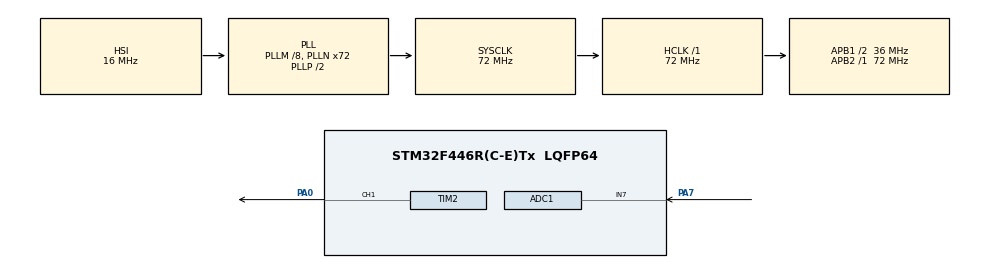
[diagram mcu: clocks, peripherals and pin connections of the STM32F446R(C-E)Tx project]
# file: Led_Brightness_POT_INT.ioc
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ADC1.Channel-0\#ChannelRegularConversion=ADC_CHANNEL_7
ADC1.NbrOfConversionFlag=1
ADC1.Rank-0\#ChannelRegularConversion=1
ADC1.SamplingTime-0\#ChannelRegularConversion=ADC_SAMPLETIME_3CYCLES
ADC1.master=1
Mcu.Family=STM32F4
Mcu.Name=STM32F446R(C-E)Tx
Mcu.Package=LQFP64
NVIC.ADC_IRQn=true\:0\:0\:false\:false\:true\:true\:true\:true
NVIC.PriorityGroup=NVIC_PRIORITYGROUP_0
PA0-WKUP.Signal=S_TIM2_CH1_ETR
PA7.Signal=ADCx_IN7
PH0-OSC_IN.Mode=HSE-External-Oscillator
PH0-OSC_IN.Signal=RCC_OSC_IN
PH1-OSC_OUT.Mode=HSE-External-Oscillator
PH1-OSC_OUT.Signal=RCC_OSC_OUT
ProjectManager.HeapSize=0x200
ProjectManager.StackSize=0x400
ProjectManager.TargetToolchain=STM32CubeIDE
RCC.48MHZClocksFreq_Value=84000000
RCC.AHBFreq_Value=72000000
RCC.APB1CLKDivider=RCC_HCLK_DIV2
RCC.APB1Freq_Value=36000000
RCC.APB1TimFreq_Value=72000000
RCC.APB2Freq_Value=72000000
RCC.APB2TimFreq_Value=72000000
RCC.CortexFreq_Value=72000000
RCC.FLatency-AdvancedSettings=FLASH_LATENCY_2
RCC.HCLKFreq_Value=72000000
RCC.HSE_VALUE=8000000
RCC.HSI_VALUE=16000000
RCC.PLLM=8
RCC.PLLN=72
RCC.SYSCLKFreq_VALUE=72000000
RCC.SYSCLKSource=RCC_SYSCLKSOURCE_PLLCLK
RCC.USBFreq_Value=72000000
RCC.VCOOutputFreq_Value=144000000
SH.ADCx_IN7.0=ADC1_IN7,IN7
SH.S_TIM2_CH1_ETR.0=TIM2_CH1,PWM Generation1 CH1
TIM2.AutoReloadPreload=TIM_AUTORELOAD_PRELOAD_ENABLE
TIM2.Channel-PWM\ Generation1\ CH1=TIM_CHANNEL_1
TIM2.Period=65536
VP_TIM2_VS_ClockSourceINT.Mode=Internal
board=NUCLEO-F446RE

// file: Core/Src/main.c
/* USER CODE BEGIN Header */
/**
  ******************************************************************************
  * @file           : main.c
  * @brief          : Main program body
  ******************************************************************************
  * @attention
  *
  * Copyright (c) 2024 STMicroelectronics.
  * All rights reserved.
  *
  * This software is licensed under terms that can be found in the LICENSE file
  * in the root directory of this software component.
  * If no LICENSE file comes with this software, it is provided AS-IS.
  *
  ******************************************************************************
  */
/* USER CODE END Header */
#include "main.h"

ADC_HandleTypeDef hadc1;

TIM_HandleTypeDef htim2;

/* USER CODE BEGIN PV */
uint16_t adc_data = 0;
uint16_t pwm_value = 0;
/* USER CODE END PV */

void SystemClock_Config(void);
static void MX_GPIO_Init(void);
static void MX_ADC1_Init(void);
static void MX_TIM2_Init(void);

int main(void)
{

  /* MCU Configuration--------------------------------------------------------*/

  /* Reset of all peripherals, Initializes the Flash interface and the Systick. */
  HAL_Init();

  /* Configure the system clock */
  SystemClock_Config();

  /* Initialize all configured peripherals */
  MX_GPIO_Init();
  MX_ADC1_Init();
  MX_TIM2_Init();
  /* USER CODE BEGIN 2 */
  HAL_TIM_PWM_Start(&htim2, TIM_CHANNEL_1);
  /* USER CODE END 2 */

  /* Infinite loop */
  /* USER CODE BEGIN WHILE */
  while (1)
  {
	  HAL_ADC_Start_IT(&hadc1);
	  pwm_value = (adc_data << 3);
	  TIM2->CCR1 = pwm_value;

	  HAL_Delay(1);
    /* USER CODE END WHILE */

  }
}

void SystemClock_Config(void)
{
  RCC_OscInitTypeDef RCC_OscInitStruct = {0};
  RCC_ClkInitTypeDef RCC_ClkInitStruct = {0};

  /** Configure the main internal regulator output voltage
  */
  __HAL_RCC_PWR_CLK_ENABLE();
  __HAL_PWR_VOLTAGESCALING_CONFIG(PWR_REGULATOR_VOLTAGE_SCALE3);

  /** Initializes the RCC Oscillators according to the specified parameters
  * in the RCC_OscInitTypeDef structure.
  */
  RCC_OscInitStruct.OscillatorType = RCC_OSCILLATORTYPE_HSI;
  RCC_OscInitStruct.HSIState = RCC_HSI_ON;
  RCC_OscInitStruct.HSICalibrationValue = RCC_HSICALIBRATION_DEFAULT;
  RCC_OscInitStruct.PLL.PLLState = RCC_PLL_ON;
  RCC_OscInitStruct.PLL.PLLSource = RCC_PLLSOURCE_HSI;
  RCC_OscInitStruct.PLL.PLLM = 8;
  RCC_OscInitStruct.PLL.PLLN = 72;
  RCC_OscInitStruct.PLL.PLLP = RCC_PLLP_DIV2;
  RCC_OscInitStruct.PLL.PLLQ = 2;
  RCC_OscInitStruct.PLL.PLLR = 2;
  if (HAL_RCC_OscConfig(&RCC_OscInitStruct) != HAL_OK)
  {
    Error_Handler();
  }

  /** Initializes the CPU, AHB and APB buses clocks
  */
  RCC_ClkInitStruct.ClockType = RCC_CLOCKTYPE_HCLK|RCC_CLOCKTYPE_SYSCLK
                              |RCC_CLOCKTYPE_PCLK1|RCC_CLOCKTYPE_PCLK2;
  RCC_ClkInitStruct.SYSCLKSource = RCC_SYSCLKSOURCE_PLLCLK;
  RCC_ClkInitStruct.AHBCLKDivider = RCC_SYSCLK_DIV1;
  RCC_ClkInitStruct.APB1CLKDivider = RCC_HCLK_DIV2;
  RCC_ClkInitStruct.APB2CLKDivider = RCC_HCLK_DIV1;

  if (HAL_RCC_ClockConfig(&RCC_ClkInitStruct, FLASH_LATENCY_2) != HAL_OK)
  {
    Error_Handler();
  }
}

static void MX_ADC1_Init(void)
{

  ADC_ChannelConfTypeDef sConfig = {0};

  /** Configure the global features of the ADC (Clock, Resolution, Data Alignment and number of conversion)
  */
  hadc1.Instance = ADC1;
  hadc1.Init.ClockPrescaler = ADC_CLOCK_SYNC_PCLK_DIV2;
  hadc1.Init.Resolution = ADC_RESOLUTION_12B;
  hadc1.Init.ScanConvMode = DISABLE;
  hadc1.Init.ContinuousConvMode = DISABLE;
  hadc1.Init.DiscontinuousConvMode = DISABLE;
  hadc1.Init.ExternalTrigConvEdge = ADC_EXTERNALTRIGCONVEDGE_NONE;
  hadc1.Init.ExternalTrigConv = ADC_SOFTWARE_START;
  hadc1.Init.DataAlign = ADC_DATAALIGN_RIGHT;
  hadc1.Init.NbrOfConversion = 1;
  hadc1.Init.DMAContinuousRequests = DISABLE;
  hadc1.Init.EOCSelection = ADC_EOC_SINGLE_CONV;
  if (HAL_ADC_Init(&hadc1) != HAL_OK)
  {
    Error_Handler();
  }

  /** Configure for the selected ADC regular channel its corresponding rank in the sequencer and its sample time.
  */
  sConfig.Channel = ADC_CHANNEL_7;
  sConfig.Rank = 1;
  sConfig.SamplingTime = ADC_SAMPLETIME_3CYCLES;
  if (HAL_ADC_ConfigChannel(&hadc1, &sConfig) != HAL_OK)
  {
    Error_Handler();
  }

}

static void MX_TIM2_Init(void)
{

  TIM_ClockConfigTypeDef sClockSourceConfig = {0};
  TIM_MasterConfigTypeDef sMasterConfig = {0};
  TIM_OC_InitTypeDef sConfigOC = {0};

  htim2.Instance = TIM2;
  htim2.Init.Prescaler = 0;
  htim2.Init.CounterMode = TIM_COUNTERMODE_UP;
  htim2.Init.Period = 65536;
  htim2.Init.ClockDivision = TIM_CLOCKDIVISION_DIV1;
  htim2.Init.AutoReloadPreload = TIM_AUTORELOAD_PRELOAD_ENABLE;
  if (HAL_TIM_Base_Init(&htim2) != HAL_OK)
  {
    Error_Handler();
  }
  sClockSourceConfig.ClockSource = TIM_CLOCKSOURCE_INTERNAL;
  if (HAL_TIM_ConfigClockSource(&htim2, &sClockSourceConfig) != HAL_OK)
  {
    Error_Handler();
  }
  if (HAL_TIM_PWM_Init(&htim2) != HAL_OK)
  {
    Error_Handler();
  }
  sMasterConfig.MasterOutputTrigger = TIM_TRGO_RESET;
  sMasterConfig.MasterSlaveMode = TIM_MASTERSLAVEMODE_DISABLE;
  if (HAL_TIMEx_MasterConfigSynchronization(&htim2, &sMasterConfig) != HAL_OK)
  {
    Error_Handler();
  }
  sConfigOC.OCMode = TIM_OCMODE_PWM1;
  sConfigOC.Pulse = 0;
  sConfigOC.OCPolarity = TIM_OCPOLARITY_HIGH;
  sConfigOC.OCFastMode = TIM_OCFAST_DISABLE;
  if (HAL_TIM_PWM_ConfigChannel(&htim2, &sConfigOC, TIM_CHANNEL_1) != HAL_OK)
  {
    Error_Handler();
  }
  HAL_TIM_MspPostInit(&htim2);

}

static void MX_GPIO_Init(void)
{

  /* GPIO Ports Clock Enable */
  __HAL_RCC_GPIOH_CLK_ENABLE();
  __HAL_RCC_GPIOA_CLK_ENABLE();

}

/* USER CODE BEGIN 4 */

void HAL_ADC_ConvCpltCallback(ADC_HandleTypeDef* hadc)
{
	adc_data = HAL_ADC_GetValue(hadc);
  /* Prevent unused argument(s) compilation warning */
  UNUSED(hadc);
  /* NOTE : This function Should not be modified, when the callback is needed,
            the HAL_ADC_ConvCpltCallback could be implemented in the user file
   */
}
/* USER CODE END 4 */

void Error_Handler(void)
{
  __disable_irq();
  while (1)
  {
  }
}
